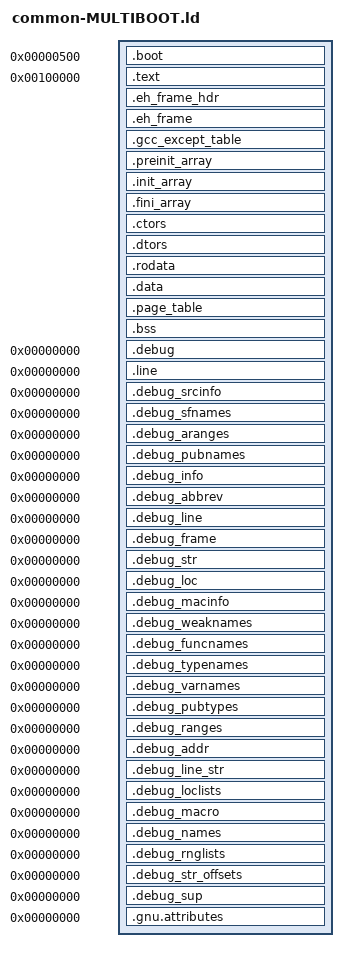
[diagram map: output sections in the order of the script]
/****************************************************************************
 *                                                                          *
 *                         GNAT COMPILER COMPONENTS                         *
 *                                                                          *
 *                               x 8 6 - 6 4                                *
 *                                                                          *
 *                            Linker Script File                            *
 *                                                                          *
 *      Copyright (C) 1999-2002 Universidad Politecnica de Madrid           *
 *             Copyright (C) 2003-2006 The European Space Agency            *
 *                   Copyright (C) 2003-2020 AdaCore                        *
 *                                                                          *
 * GNAT is free software;  you can  redistribute it  and/or modify it under *
 * terms of the  GNU General Public License as published  by the Free Soft- *
 * ware  Foundation;  either version 2,  or (at your option) any later ver- *
 * sion.  GNAT is distributed in the hope that it will be useful, but WITH- *
 * OUT ANY WARRANTY;  without even the  implied warranty of MERCHANTABILITY *
 * or FITNESS FOR A PARTICULAR PURPOSE.  See the GNU General Public License *
 * for  more details.  You should have  received  a copy of the GNU General *
 * Public License  distributed with GNAT;  see file COPYING.  If not, write *
 * to  the  Free Software Foundation,  51  Franklin  Street,  Fifth  Floor, *
 * Boston, MA 02110-1301, USA.                                              *
 *                                                                          *
 * As a  special  exception,  if you  link  this file  with other  files to *
 * produce an executable,  this file does not by itself cause the resulting *
 * executable to be covered by the GNU General Public License. This except- *
 * ion does not  however invalidate  any other reasons  why the  executable *
 * file might be covered by the  GNU Public License.                        *
 *                                                                          *
 * GNARL was developed by the GNARL team at Florida State University.       *
 * Extensive contributions were provided by Ada Core Technologies, Inc.     *
 * The  executive  was developed  by the  Real-Time  Systems  Group  at the *
 * Technical University of Madrid.                                          *
 *                                                                          *
 ****************************************************************************/

/* Linker script for starting the application from GRUB2 or other multiboot2
 * compliant bootloader. */

INCLUDE memory-map.ld

_DEFAULT_STACK_SIZE = 2*1024*1024;

ENTRY(__start32);

/* Drag in the Multiboot header kicking and screaming into the binary */

EXTERN(__magic_address);

SECTIONS
{
  /* The boot code needs to be located in first 64KiB to accommodate the
   * initial 16-bit boot code. We keep the rest of the bootcode here for
   * simplicity. */

  .boot 0x500:
  {
    __text_start = .;
    KEEP (*(.multiboot))
    *(.boottext16)
    *(.boottext32)
    *(.boottext64)
    *(.gdt)
  } > ram

  /* Place the rest of the image above 1MB to avoid the memory hole at
   * 0x90000-0xFFFFF */

  .text 1M :
  {
    __text = .;
    *(.plt)
    KEEP (*(.init))
    KEEP (*(.fini))
    *(.text .text.* .gnu.linkonce.t*)
    *(.gnu.warning)
  } > ram

  .eh_frame_hdr :
  {
    __eh_frame_hdr = .;
    *(.eh_frame_hdr)
  } > ram

  .eh_frame :
  {
    __EH_FRAME__ = .;
    KEEP(*(.eh_frame))
    LONG(0);
  } > ram

  .gcc_except_table :
  {
      *(.gcc_except_table .gcc_except_table.*)
  } > ram

  .preinit_array     :
  {
    PROVIDE_HIDDEN (__preinit_array_start = .);
    KEEP (*(.preinit_array))
    PROVIDE_HIDDEN (__preinit_array_end = .);
  } > ram

  .init_array     :
  {
    PROVIDE_HIDDEN (__init_array_start = .);
    KEEP (*(SORT_BY_INIT_PRIORITY(.init_array.*) SORT_BY_INIT_PRIORITY(.ctors.*)))
    KEEP (*(.init_array EXCLUDE_FILE (*crtbegin.o *crtbegin?.o *crtend.o *crtend?.o ) .ctors))
    PROVIDE_HIDDEN (__init_array_end = .);
  } > ram

  .fini_array     :
  {
    PROVIDE_HIDDEN (__fini_array_start = .);
    KEEP (*(SORT_BY_INIT_PRIORITY(.fini_array.*) SORT_BY_INIT_PRIORITY(.dtors.*)))
    KEEP (*(.fini_array EXCLUDE_FILE (*crtbegin.o *crtbegin?.o *crtend.o *crtend?.o ) .dtors))
    PROVIDE_HIDDEN (__fini_array_end = .);
  } > ram

  .ctors          :
  {
    /* gcc uses crtbegin.o to find the start of
       the constructors, so we make sure it is
       first.  Because this is a wildcard, it
       doesn't matter if the user does not
       actually link against crtbegin.o; the
       linker won't look for a file to match a
       wildcard.  The wildcard also means that it
       doesn't matter which directory crtbegin.o
       is in.  */
    KEEP (*crtbegin.o(.ctors))
    KEEP (*crtbegin?.o(.ctors))
    /* We don't want to include the .ctor section from
       the crtend.o file until after the sorted ctors.
       The .ctor section from the crtend file contains the
       end of ctors marker and it must be last */
    KEEP (*(EXCLUDE_FILE (*crtend.o *crtend?.o ) .ctors))
    KEEP (*(SORT(.ctors.*)))
    KEEP (*(.ctors))
  } > ram

  .dtors          :
  {
    KEEP (*crtbegin.o(.dtors))
    KEEP (*crtbegin?.o(.dtors))
    KEEP (*(EXCLUDE_FILE (*crtend.o *crtend?.o ) .dtors))
    KEEP (*(SORT(.dtors.*)))
    KEEP (*(.dtors))
  } > ram

  .rodata :
  {
    *(.lit)
    *(.rodata .rodata.* .gnu.linkonce.r*)
    *(.rodata1 rodata1.*)
    . = ALIGN(16);
  } > ram

  .data :
  {
    __data = .;
    __data_start = .;
    *(.got.plt) *(.igot.plt) *(.got) *(.igot) /* minimal PIC support */
    *(.data .data.* .gnu.linkonce.d*)
    *(.data1 data1.*)

    /* Ensure that the end of the data section is always word aligned.
       Initial values are stored in 16-bytes blocks so we must guarantee
       that these blocks do not fall out the section (otherwise they are
       truncated and the initial data for the last block are lost). */

    . = ALIGN(16);
    __data_end = .;
  } > ram

  .page_table (NOLOAD) :
  {
   /* Align the start and end of the bss section on 64-byte boundaries for
     faster zeroing */
    . = ALIGN(64);
    *(.page_table)
  } > ram

  .bss (NOLOAD):
  {
   /* Align the start and end of the bss section on 64-byte boundaries for
     faster zeroing */
   . = ALIGN(64);
   __bss_start = .;
   *(.bss .bss.*)
   *(COMMON)

   . = ALIGN(64);
   __bss_end = .;

   /* Interrupt stacks. Statically allocated in System.BB.Interrupts */
   __interrupt_stack_start = .;
   *(.interrupt_stacks)
   . = ALIGN(64); /* Align stacks to 512 bits in case we need to store AVX-512 registers */
   __interrupt_stack_end = .;

   __stack_start = .;
   . += DEFINED (__stack_size) ? __stack_size : _DEFAULT_STACK_SIZE;
   . = ALIGN(16); /* Stack needs to be 16 bytes aligned */
   __stack_end = .;

   _end = .;
   __heap_start = .;
   __heap_end = ORIGIN(ram) + LENGTH(ram);
  } > ram

  __bss_size = (__bss_end - __bss_start);

  /* DWARF debug sections.
     Symbols in the DWARF debugging sections are relative to the beginning
     of the section so we begin them at 0.  */

  /* DWARF 1.  */
  .debug          0 : { *(.debug) }
  .line           0 : { *(.line) }

  /* GNU DWARF 1 extensions.  */
  .debug_srcinfo  0 : { *(.debug_srcinfo) }
  .debug_sfnames  0 : { *(.debug_sfnames) }

  /* DWARF 1.1 and DWARF 2.  */
  .debug_aranges  0 : { *(.debug_aranges) }
  .debug_pubnames 0 : { *(.debug_pubnames) }

  /* DWARF 2.  */
  .debug_info     0 : { *(.debug_info .gnu.linkonce.wi.*) }
  .debug_abbrev   0 : { *(.debug_abbrev) }
  .debug_line     0 : { *(.debug_line .debug_line.* .debug_line_end) }
  .debug_frame    0 : { *(.debug_frame) }
  .debug_str      0 : { *(.debug_str) }
  .debug_loc      0 : { *(.debug_loc) }
  .debug_macinfo  0 : { *(.debug_macinfo) }

  /* SGI/MIPS DWARF 2 extensions.  */
  .debug_weaknames 0 : { *(.debug_weaknames) }
  .debug_funcnames 0 : { *(.debug_funcnames) }
  .debug_typenames 0 : { *(.debug_typenames) }
  .debug_varnames  0 : { *(.debug_varnames) }

  /* DWARF 3.  */
  .debug_pubtypes 0 : { *(.debug_pubtypes) }
  .debug_ranges   0 : { *(.debug_ranges) }

  /* DWARF 5.  */
  .debug_addr     0 : { *(.debug_addr) }
  .debug_line_str 0 : { *(.debug_line_str) }
  .debug_loclists 0 : { *(.debug_loclists) }
  .debug_macro    0 : { *(.debug_macro) }
  .debug_names    0 : { *(.debug_names) }
  .debug_rnglists 0 : { *(.debug_rnglists) }
  .debug_str_offsets 0 : { *(.debug_str_offsets) }
  .debug_sup      0 : { *(.debug_sup) }

  .gnu.attributes 0 : { KEEP (*(.gnu.attributes)) }
  /DISCARD/ :
  { *(.bios_replacement)
    *(.note.GNU-stack)
    *(.gnu_debuglink)
    *(.gnu.lto_*)}
}

